# CH585SFR register map
Vendor: WCH Ltd.; Series: CH58x; File version: 1.0
CPU: RISC-V r0p0, little endian, no MPU, no FPU, 2 interrupt priority bits
Registers are 8-bit, Read or Write, reset 0x0 unless marked. A register's access mark holds for its fields unless they carry their own. Offsets are from the block's base; [hi:lo] are bit positions; lines under a group give offsets from that group; {n}, {i} and the like mark numbered series.

## PWMx
Base 0x40005000
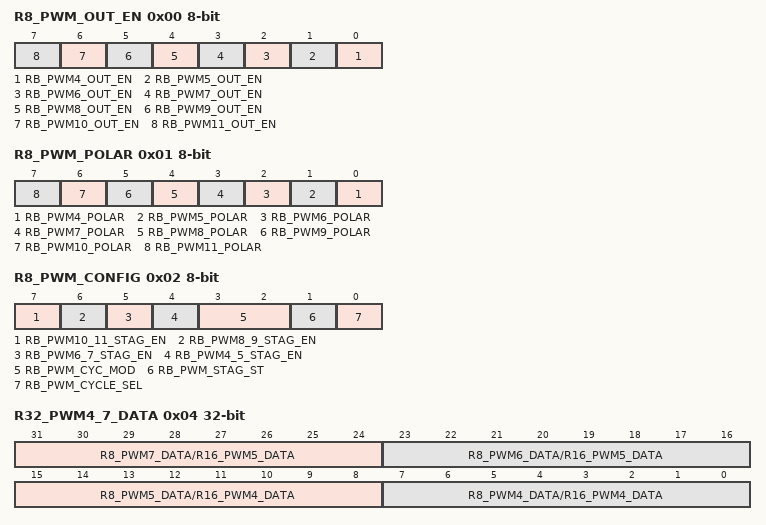
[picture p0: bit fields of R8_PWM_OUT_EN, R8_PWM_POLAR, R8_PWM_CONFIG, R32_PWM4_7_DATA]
0x00 R8_PWM_OUT_EN — RW, PWM output enable control
  [n-4] RB_PWM{n}_OUT_EN (n=4..11) — RW, PWM{n} output enable
0x01 R8_PWM_POLAR — RW, PWM output polarity control
  [n-4] RB_PWM{n}_POLAR (n=4..11) — RW, PWM{n} output polarity: 0=default low and high action, 1=default high and low action
0x02 R8_PWM_CONFIG reset not defined — RW, PWM configuration
  [7] RB_PWM10_11_STAG_EN — RW, PWM10/11 stagger output enable: 0=independent output, 1=stagger output
  [6] RB_PWM8_9_STAG_EN — RW, PWM8/9 stagger output enable: 0=independent output, 1=stagger output
  [5] RB_PWM6_7_STAG_EN — RW, PWM6/7 stagger output enable: 0=independent output, 1=stagger output
  [4] RB_PWM4_5_STAG_EN — RW, PWM4/5 stagger output enable: 0=independent output, 1=stagger output
  [3:2] RB_PWM_CYC_MOD — RW, PWM data width mode: 00=8 bits data, 01=7 bits data, 10=6 bits data, 11=5 bits data
  [1] RB_PWM_STAG_ST ro — RO, PWM stagger cycle status
  [0] RB_PWM_CYCLE_SEL — RW, PWM cycle selection: 0=256;128;64;32 clocks, 1=255;127;63;31 clocks
0x03 R8_PWM_CLOCK_DIV — RW, PWM clock divisor
0x04 R32_PWM4_7_DATA 32-bit reset not defined — RW, PWM data retention register group 1
  [31:24] R8_PWM7_DATA/R16_PWM5_DATA — RW, PWM7 data holding or PWM5 data holding(16bits wide)
  [23:16] R8_PWM6_DATA/R16_PWM5_DATA — RW, PWM6 data holding or PWM5 data holding(16bits wide)
  [15:8] R8_PWM5_DATA/R16_PWM4_DATA — RW, PWM5 data holding or PWM4 data holding(16bits wide)
  [7:0] R8_PWM4_DATA/R16_PWM4_DATA — RW, PWM4 data holding or PWM4 data holding(16bits wide)
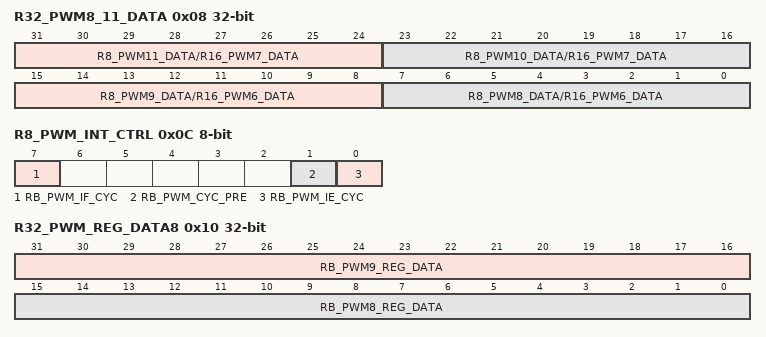
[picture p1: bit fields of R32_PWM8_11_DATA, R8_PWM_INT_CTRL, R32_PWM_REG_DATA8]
0x08 R32_PWM8_11_DATA 32-bit reset not defined — RW, PWM data retention register group 2
  [31:24] R8_PWM11_DATA/R16_PWM7_DATA — RW, PWM11 data holding or PWM7 data holding(16bits wide)
  [23:16] R8_PWM10_DATA/R16_PWM7_DATA — RW, PWM10 data holding or PWM7 data holding(16bits wide)
  [15:8] R8_PWM9_DATA/R16_PWM6_DATA — RW, PWM9 data holding or PWM6 data holding(16bits wide)
  [7:0] R8_PWM8_DATA/R16_PWM6_DATA — RW, PWM8 data holding or PWM6 data holding(16bits wide)
0x0C R8_PWM_INT_CTRL — RW, PWM interrupt control
  [7] RB_PWM_IF_CYC — RW1, interrupt flag for PWM cycle end
  [1] RB_PWM_CYC_PRE — RW, select PWM cycle interrupt point
  [0] RB_PWM_IE_CYC — RW, enable interrupt for PWM cycle end
0x10 R32_PWM_REG_DATA8 32-bit reset not defined — RW, PWM8/9 data register
  [31:16] RB_PWM9_REG_DATA — RW, 16 bit data of PWM9 channel
  [15:0] RB_PWM8_REG_DATA — RW, 16 bit data of PWM8 channel
0x14 R32_PWM_REG_CYCLE 32-bit reset not defined — RW, PWM cycle end register
  [15:0] RB_PWM_CYC_VALUE — RW, PWM End Cycles

## LCD
Base 0x40006000
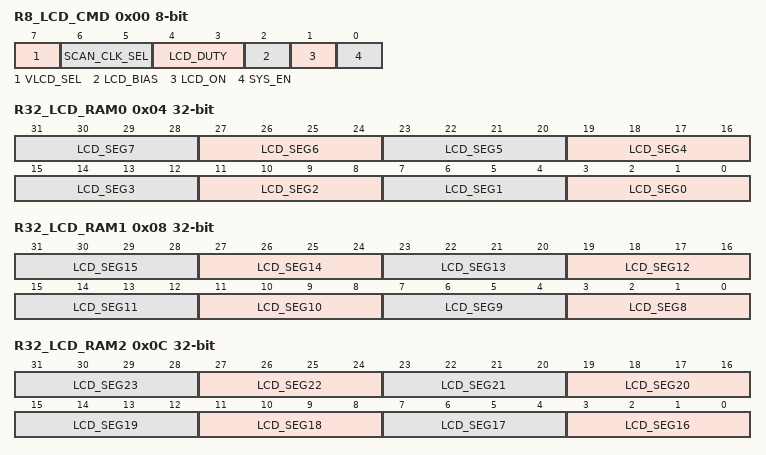
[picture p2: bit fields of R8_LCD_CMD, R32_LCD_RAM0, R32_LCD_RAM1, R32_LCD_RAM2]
0x00 R8_LCD_CMD — RW, LCD Command Register
  [7] VLCD_SEL — RW, LCD driver voltage selection
  [6:5] SCAN_CLK_SEL — RW, Scan clock selection
  [4:3] LCD_DUTY — RW, LCD duty cycle selection
  [2] LCD_BIAS — RW, PWM6 Bias ratio selection enable
  [1] LCD_ON — RW, LCD switch
  [0] SYS_EN — RW, System Enable
0x04 R32_LCD_RAM0 32-bit — RW, LCD RAM0 register
  [4n+3:4n] LCD_SEG{n} (n=0..7) — RW, SEG{n} segment data
0x08 R32_LCD_RAM1 32-bit — RW, LCD RAM1 register
  [4n-29:4n-32] LCD_SEG{n} (n=8..15) — RW, SEG{n} segment data
0x0C R32_LCD_RAM2 32-bit — RW, LCD RAM2 register
  [4n-61:4n-64] LCD_SEG{n} (n=16..23) — RW, SEG{n} segment data
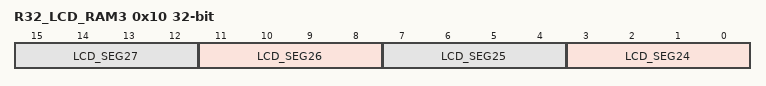
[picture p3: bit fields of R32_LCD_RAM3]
0x10 R32_LCD_RAM3 32-bit — RW, LCD RAM3 register
  [4n-93:4n-96] LCD_SEG{n} (n=24..27) — RW, SEG{n} segment data
0x14 R32_LCD_SEG_EN 32-bit — RW, LCD segment enable register
  [27:0] RB_LCD_SEG_EN — RW, Enable SEG0-SEG27 segment, high level effective

## LED
Base 0x4000F000
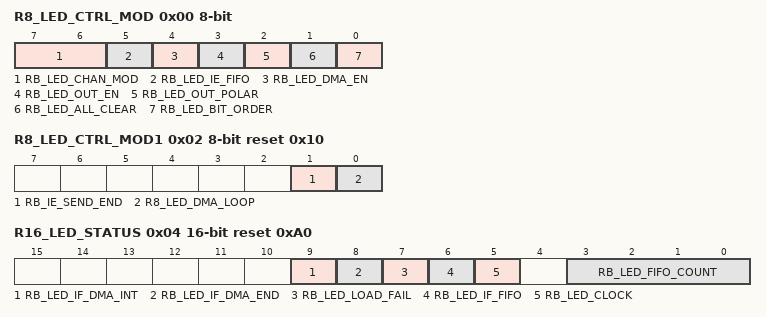
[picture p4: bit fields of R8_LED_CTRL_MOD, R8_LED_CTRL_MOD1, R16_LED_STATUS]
0x00 R8_LED_CTRL_MOD Read and Write — RW, LED mode configuration register
  [7:6] RB_LED_CHAN_MOD — LED channel mode selection
  [5] RB_LED_IE_FIFO — FIFO count over half interrupt enabled
  [4] RB_LED_DMA_EN — LED DMA function and DMA interrupt enable
  [3] RB_LED_OUT_EN — LED signal output enable
  [2] RB_LED_OUT_POLAR — LED data output polarity control bit
  [1] RB_LED_ALL_CLEAR — LED FIFO/counter/interrupt flag reset to zero
  [0] RB_LED_BIT_ORDER — Selection of LED serial data bit sequence
0x01 R8_LED_CLOCK_DIV Read and Write reset 0x10 — RW, LED serial clock divider register
  [7:0] R8_LED_CLOCK_DIV — LED output clock frequency division coefficient
0x02 R8_LED_CTRL_MOD1 Read and Write reset 0x10 — RW, LED mode configuration register 1
  [1] RB_IE_SEND_END — DMA All Data Transfer End Interrupt Enable
  [0] R8_LED_DMA_LOOP — Enable LED DMA data cycling usage
0x04 R16_LED_STATUS 16-bit RW1 reset 0xA0 — RW1, LED status register
  [9] RB_LED_IF_DMA_INT — DMA transfer end interrupt flag bit
  [8] RB_LED_IF_DMA_END — DMA completion flag, write 1 to reset or write R16_SED-DMA_CNT to reset
  [7] RB_LED_LOAD_FAIL — Loading data results
  [6] RB_LED_IF_FIFO — FIFO count over half interrupt flag, write 1 to reset or write R16_SED_LFO to reset
  [5] RB_LED_CLOCK — Current LED clock signal level status
  [3:0] RB_LED_FIFO_COUNT — The byte count value in the current FIFO must be even
0x08 R32_LED_FIFO 32-bit wo reset not defined — WO, LED data FIFO register
  [31:0] R32_LED_FIFO — LED data FIFO input, 32-bit write
0x10 R16_LED_DMA_LEN 16-bit wo reset not defined — WO, LED DMA transmission length
  [11:0] R16_LED_DMA_LENGTH — DMA transmission count length
0x14 R16_LED_DMA_CNT 16-bit wo — WO, LED DMA remaining count register
  [11:0] RB_LED_DMA_CNT — LED_SMA_maIN Main Buffer Current DMA Remaining Words (16 bits) Count
0x18 R32_LED_DMA_BEG 32-bit Read and Write reset not defined — RW, LED DMA starting address
  [16:2] RB_LED_DMA_BEG — DMA starting address
0x1C R32_LED_DMA_CUR 32-bit ro reset not defined — RO, LED DMA current address
  [16:2] RB_LED_DMA_CUR — LED DMA current address

## Systick
Base 0xE000F000
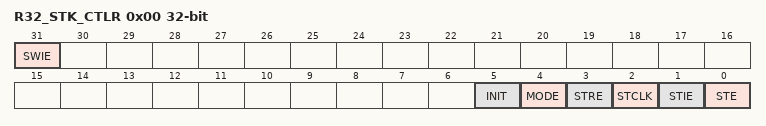
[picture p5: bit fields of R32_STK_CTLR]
0x00 R32_STK_CTLR 32-bit — Systick counter control register
  [31] SWIE — RW0,System soft interrupt enable
  [5] INIT — Initial counter value updated
  [4] MODE — counter mode
  [3] STRE — System counter reload control
  [2] STCLK — System counter clock Source selection
  [1] STIE — Systick counter interrupt enable
  [0] STE — Systick counter enable
0x04 R32_STK_SR 32-bit — Systick count status register
  [0] CNTIF — RW,CNTIF
0x08 R32_STK_CNTL 32-bit — Systick counter low register
  [31:0] CNTL — RW,CNTL
0x0C R32_STK_CNTH 32-bit — Systick counter high register
  [31:0] CNTH — RW,CNTH
0x10 R32_STK_CMPLR 32-bit — Systick compare low register
  [31:0] CMPL — RW,CMPL
0x14 R32_STK_CMPHR 32-bit — Systick compare high register
  [31:0] CMPH — RW,CMPH
